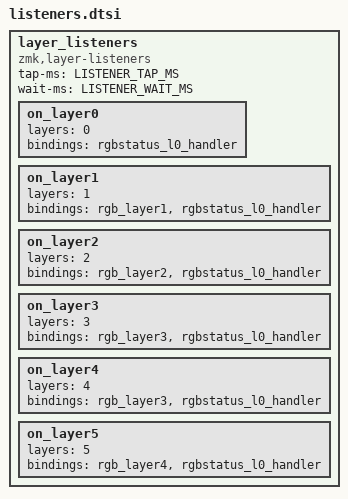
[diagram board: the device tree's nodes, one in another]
    layer_listeners {
        compatible = "zmk,layer-listeners";
        tap-ms = <LISTENER_TAP_MS>;
        wait-ms = <LISTENER_WAIT_MS>;

        on_layer0 { layers = <0>; bindings = <&rgbstatus_l0_handler>; };
        on_layer1 { layers = <1>; bindings = <&rgb_layer1 &rgbstatus_l0_handler>; };
        on_layer2 { layers = <2>; bindings = <&rgb_layer2 &rgbstatus_l0_handler>; };
        on_layer3 { layers = <3>; bindings = <&rgb_layer3 &rgbstatus_l0_handler>; };
        on_layer4 { layers = <4>; bindings = <&rgb_layer3 &rgbstatus_l0_handler>; };
        on_layer5 { layers = <5>; bindings = <&rgb_layer4 &rgbstatus_l0_handler>; };
    };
